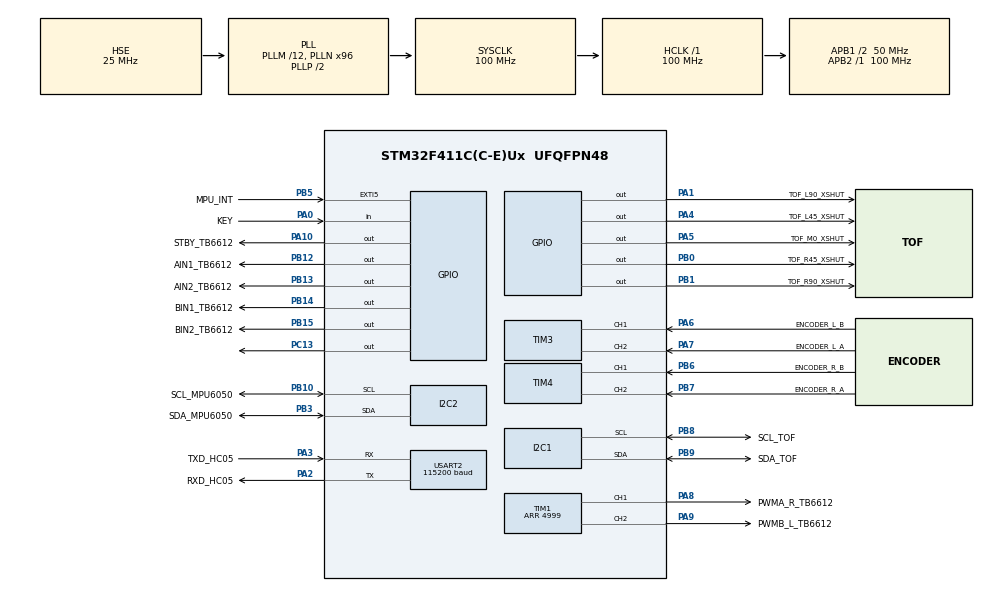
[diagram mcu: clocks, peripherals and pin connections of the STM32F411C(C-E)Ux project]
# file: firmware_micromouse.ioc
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Dma.Request0=USART2_RX
Dma.Request1=USART2_TX
Dma.USART2_RX.0.Direction=DMA_PERIPH_TO_MEMORY
Dma.USART2_RX.0.FIFOMode=DMA_FIFOMODE_DISABLE
Dma.USART2_RX.0.Instance=DMA1_Stream5
Dma.USART2_RX.0.MemDataAlignment=DMA_MDATAALIGN_BYTE
Dma.USART2_RX.0.MemInc=DMA_MINC_ENABLE
Dma.USART2_RX.0.Mode=DMA_CIRCULAR
Dma.USART2_RX.0.PeriphDataAlignment=DMA_PDATAALIGN_BYTE
Dma.USART2_RX.0.PeriphInc=DMA_PINC_DISABLE
Dma.USART2_RX.0.Priority=DMA_PRIORITY_LOW
Dma.USART2_TX.1.Direction=DMA_MEMORY_TO_PERIPH
Dma.USART2_TX.1.FIFOMode=DMA_FIFOMODE_DISABLE
Dma.USART2_TX.1.Instance=DMA1_Stream6
Dma.USART2_TX.1.MemDataAlignment=DMA_MDATAALIGN_BYTE
Dma.USART2_TX.1.MemInc=DMA_MINC_ENABLE
Dma.USART2_TX.1.Mode=DMA_NORMAL
Dma.USART2_TX.1.PeriphDataAlignment=DMA_PDATAALIGN_BYTE
Dma.USART2_TX.1.PeriphInc=DMA_PINC_DISABLE
Dma.USART2_TX.1.Priority=DMA_PRIORITY_LOW
I2C1.I2C_Mode=I2C_Fast
I2C2.I2C_Mode=I2C_Fast
Mcu.Family=STM32F4
Mcu.Name=STM32F411C(C-E)Ux
Mcu.Package=UFQFPN48
NVIC.DMA1_Stream5_IRQn=true\:3\:0\:false\:false\:true\:false\:true\:true
NVIC.DMA1_Stream6_IRQn=true\:3\:0\:false\:false\:true\:false\:true\:true
NVIC.EXTI9_5_IRQn=true\:2\:0\:false\:false\:true\:true\:true\:true
NVIC.PriorityGroup=NVIC_PRIORITYGROUP_4
NVIC.TIM2_IRQn=true\:1\:0\:false\:false\:true\:true\:true\:true
NVIC.USART2_IRQn=true\:3\:0\:false\:false\:true\:true\:true\:true
PA0-WKUP.GPIO_Label=KEY
PA0-WKUP.GPIO_PuPd=GPIO_PULLUP
PA0-WKUP.Signal=GPIO_Input
PA1.GPIO_Label=TOF_L90_XSHUT
PA1.Signal=GPIO_Output
PA10.GPIO_Label=STBY_TB6612
PA10.Signal=GPIO_Output
PA13.Mode=Serial_Wire
PA13.Signal=SYS_JTMS-SWDIO
PA14.Mode=Serial_Wire
PA14.Signal=SYS_JTCK-SWCLK
PA2.GPIO_Label=RXD_HC05
PA2.Mode=Asynchronous
PA2.Signal=USART2_TX
PA3.GPIO_Label=TXD_HC05
PA3.Mode=Asynchronous
PA3.Signal=USART2_RX
PA4.GPIO_Label=TOF_L45_XSHUT
PA4.Signal=GPIO_Output
PA5.GPIO_Label=TOF_M0_XSHUT
PA5.Signal=GPIO_Output
PA6.GPIO_Label=ENCODER_L_B
PA6.Signal=S_TIM3_CH1
PA7.GPIO_Label=ENCODER_L_A
PA7.Signal=S_TIM3_CH2
PA8.GPIO_Label=PWMA_R_TB6612
PA8.Signal=S_TIM1_CH1
PA9.GPIO_Label=PWMB_L_TB6612
PA9.Signal=S_TIM1_CH2
PB0.GPIO_Label=TOF_R45_XSHUT
PB0.Signal=GPIO_Output
PB1.GPIO_Label=TOF_R90_XSHUT
PB1.Signal=GPIO_Output
PB10.GPIO_Label=SCL_MPU6050
PB10.Mode=I2C
PB10.Signal=I2C2_SCL
PB12.GPIO_Label=AIN1_TB6612
PB12.Signal=GPIO_Output
PB13.GPIO_Label=AIN2_TB6612
PB13.Signal=GPIO_Output
PB14.GPIO_Label=BIN1_TB6612
PB14.Signal=GPIO_Output
PB15.GPIO_Label=BIN2_TB6612
PB15.Signal=GPIO_Output
PB3.GPIO_Label=SDA_MPU6050
PB3.Mode=I2C
PB3.Signal=I2C2_SDA
PB5.GPIO_Label=MPU_INT
PB5.Signal=GPXTI5
PB6.GPIO_Label=ENCODER_R_B
PB6.Signal=S_TIM4_CH1
PB7.GPIO_Label=ENCODER_R_A
PB7.Signal=S_TIM4_CH2
PB8.GPIO_Label=SCL_TOF
PB8.Mode=I2C
PB8.Signal=I2C1_SCL
PB9.GPIO_Label=SDA_TOF
PB9.Mode=I2C
PB9.Signal=I2C1_SDA
PC13-ANTI_TAMP.Signal=GPIO_Output
PH0\ -\ OSC_IN.Mode=HSE-External-Oscillator
PH0\ -\ OSC_IN.Signal=RCC_OSC_IN
PH1\ -\ OSC_OUT.Mode=HSE-External-Oscillator
PH1\ -\ OSC_OUT.Signal=RCC_OSC_OUT
ProjectManager.HeapSize=0x200
ProjectManager.StackSize=0x400
ProjectManager.TargetToolchain=CMake
RCC.48MHZClocksFreq_Value=50000000
RCC.AHBFreq_Value=100000000
RCC.APB1CLKDivider=RCC_HCLK_DIV2
RCC.APB1Freq_Value=50000000
RCC.APB1TimFreq_Value=100000000
RCC.APB2Freq_Value=100000000
RCC.APB2TimFreq_Value=100000000
RCC.CortexFreq_Value=100000000
RCC.HCLKFreq_Value=100000000
RCC.HSE_VALUE=25000000
RCC.HSI_VALUE=16000000
RCC.LSE_VALUE=32768
RCC.PLLM=12
RCC.PLLN=96
RCC.PLLSourceVirtual=RCC_PLLSOURCE_HSE
RCC.SYSCLKFreq_VALUE=100000000
RCC.SYSCLKSource=RCC_SYSCLKSOURCE_PLLCLK
RCC.VCOOutputFreq_Value=200000000
SH.S_TIM1_CH1.0=TIM1_CH1,PWM Generation1 CH1
SH.S_TIM1_CH2.0=TIM1_CH2,PWM Generation2 CH2
SH.S_TIM3_CH1.0=TIM3_CH1,Encoder_Interface
SH.S_TIM3_CH2.0=TIM3_CH2,Encoder_Interface
SH.S_TIM4_CH1.0=TIM4_CH1,Encoder_Interface
SH.S_TIM4_CH2.0=TIM4_CH2,Encoder_Interface
TIM1.Channel-PWM\ Generation1\ CH1=TIM_CHANNEL_1
TIM1.Channel-PWM\ Generation2\ CH2=TIM_CHANNEL_2
TIM1.Period=4999
TIM2.Period=999
TIM2.Prescaler=99
TIM3.EncoderMode=TIM_ENCODERMODE_TI12
TIM3.IC1Filter=6
TIM3.IC2Filter=6
TIM4.EncoderMode=TIM_ENCODERMODE_TI12
TIM4.IC1Filter=6
TIM4.IC2Filter=6
USART2.BaudRate=115200
USART2.VirtualMode=VM_ASYNC
VP_TIM2_VS_ClockSourceINT.Mode=Internal
board=custom

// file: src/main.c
/* USER CODE BEGIN Header */
/**
  ******************************************************************************
  * @file           : main.c
  * @brief          : Main program body
  ******************************************************************************
  * @attention
  *
  * Copyright (c) 2026 STMicroelectronics.
  * All rights reserved.
  *
  * This software is licensed under terms that can be found in the LICENSE file
  * in the root directory of this software component.
  * If no LICENSE file comes with this software, it is provided AS-IS.
  *
  ******************************************************************************
  */
/* USER CODE END Header */
#include "main.h"

/* USER CODE BEGIN Includes */
#ifdef HW_TEST
#include "hwtest/hwtest.h" /* firmware test phần cứng (env hwtest) */
#endif

/* USER CODE END Includes */

I2C_HandleTypeDef hi2c1;
I2C_HandleTypeDef hi2c2;

TIM_HandleTypeDef htim1;
TIM_HandleTypeDef htim2;
TIM_HandleTypeDef htim3;
TIM_HandleTypeDef htim4;

UART_HandleTypeDef huart2;
DMA_HandleTypeDef hdma_usart2_rx;
DMA_HandleTypeDef hdma_usart2_tx;

void SystemClock_Config(void);
static void MX_GPIO_Init(void);
static void MX_DMA_Init(void);
static void MX_I2C1_Init(void);
static void MX_I2C2_Init(void);
static void MX_TIM1_Init(void);
static void MX_TIM3_Init(void);
static void MX_TIM4_Init(void);
static void MX_USART2_UART_Init(void);
static void MX_TIM2_Init(void);

int main(void)
{

  /* MCU Configuration--------------------------------------------------------*/

  /* Reset of all peripherals, Initializes the Flash interface and the Systick. */
  HAL_Init();

  /* Configure the system clock */
  SystemClock_Config();

  /* Initialize all configured peripherals */
  MX_GPIO_Init();
  MX_DMA_Init();
  MX_I2C1_Init();
  MX_I2C2_Init();
  MX_TIM1_Init();
  MX_TIM3_Init();
  MX_TIM4_Init();
  MX_USART2_UART_Init();
  MX_TIM2_Init();
  /* USER CODE BEGIN 2 */
#ifdef HW_TEST
  hwtest_run();
#endif

  /* USER CODE END 2 */

  /* Infinite loop */
  while (1)
  {

  }
}

void SystemClock_Config(void)
{
  RCC_OscInitTypeDef RCC_OscInitStruct = {0};
  RCC_ClkInitTypeDef RCC_ClkInitStruct = {0};

  /** Configure the main internal regulator output voltage
  */
  __HAL_RCC_PWR_CLK_ENABLE();
  __HAL_PWR_VOLTAGESCALING_CONFIG(PWR_REGULATOR_VOLTAGE_SCALE1);

  /** Initializes the RCC Oscillators according to the specified parameters
  * in the RCC_OscInitTypeDef structure.
  */
  RCC_OscInitStruct.OscillatorType = RCC_OSCILLATORTYPE_HSE;
  RCC_OscInitStruct.HSEState = RCC_HSE_ON;
  RCC_OscInitStruct.PLL.PLLState = RCC_PLL_ON;
  RCC_OscInitStruct.PLL.PLLSource = RCC_PLLSOURCE_HSE;
  RCC_OscInitStruct.PLL.PLLM = 12;
  RCC_OscInitStruct.PLL.PLLN = 96;
  RCC_OscInitStruct.PLL.PLLP = RCC_PLLP_DIV2;
  RCC_OscInitStruct.PLL.PLLQ = 4;
  if (HAL_RCC_OscConfig(&RCC_OscInitStruct) != HAL_OK)
  {
    Error_Handler();
  }

  /** Initializes the CPU, AHB and APB buses clocks
  */
  RCC_ClkInitStruct.ClockType = RCC_CLOCKTYPE_HCLK|RCC_CLOCKTYPE_SYSCLK
                              |RCC_CLOCKTYPE_PCLK1|RCC_CLOCKTYPE_PCLK2;
  RCC_ClkInitStruct.SYSCLKSource = RCC_SYSCLKSOURCE_PLLCLK;
  RCC_ClkInitStruct.AHBCLKDivider = RCC_SYSCLK_DIV1;
  RCC_ClkInitStruct.APB1CLKDivider = RCC_HCLK_DIV2;
  RCC_ClkInitStruct.APB2CLKDivider = RCC_HCLK_DIV1;

  if (HAL_RCC_ClockConfig(&RCC_ClkInitStruct, FLASH_LATENCY_3) != HAL_OK)
  {
    Error_Handler();
  }
}

static void MX_I2C1_Init(void)
{

  hi2c1.Instance = I2C1;
  hi2c1.Init.ClockSpeed = 400000;
  hi2c1.Init.DutyCycle = I2C_DUTYCYCLE_2;
  hi2c1.Init.OwnAddress1 = 0;
  hi2c1.Init.AddressingMode = I2C_ADDRESSINGMODE_7BIT;
  hi2c1.Init.DualAddressMode = I2C_DUALADDRESS_DISABLE;
  hi2c1.Init.OwnAddress2 = 0;
  hi2c1.Init.GeneralCallMode = I2C_GENERALCALL_DISABLE;
  hi2c1.Init.NoStretchMode = I2C_NOSTRETCH_DISABLE;
  if (HAL_I2C_Init(&hi2c1) != HAL_OK)
  {
    Error_Handler();
  }

}

static void MX_I2C2_Init(void)
{

  hi2c2.Instance = I2C2;
  hi2c2.Init.ClockSpeed = 400000;
  hi2c2.Init.DutyCycle = I2C_DUTYCYCLE_2;
  hi2c2.Init.OwnAddress1 = 0;
  hi2c2.Init.AddressingMode = I2C_ADDRESSINGMODE_7BIT;
  hi2c2.Init.DualAddressMode = I2C_DUALADDRESS_DISABLE;
  hi2c2.Init.OwnAddress2 = 0;
  hi2c2.Init.GeneralCallMode = I2C_GENERALCALL_DISABLE;
  hi2c2.Init.NoStretchMode = I2C_NOSTRETCH_DISABLE;
  if (HAL_I2C_Init(&hi2c2) != HAL_OK)
  {
    Error_Handler();
  }

}

static void MX_TIM1_Init(void)
{

  TIM_MasterConfigTypeDef sMasterConfig = {0};
  TIM_OC_InitTypeDef sConfigOC = {0};
  TIM_BreakDeadTimeConfigTypeDef sBreakDeadTimeConfig = {0};

  htim1.Instance = TIM1;
  htim1.Init.Prescaler = 0;
  htim1.Init.CounterMode = TIM_COUNTERMODE_UP;
  htim1.Init.Period = 4999;
  htim1.Init.ClockDivision = TIM_CLOCKDIVISION_DIV1;
  htim1.Init.RepetitionCounter = 0;
  htim1.Init.AutoReloadPreload = TIM_AUTORELOAD_PRELOAD_DISABLE;
  if (HAL_TIM_PWM_Init(&htim1) != HAL_OK)
  {
    Error_Handler();
  }
  sMasterConfig.MasterOutputTrigger = TIM_TRGO_RESET;
  sMasterConfig.MasterSlaveMode = TIM_MASTERSLAVEMODE_DISABLE;
  if (HAL_TIMEx_MasterConfigSynchronization(&htim1, &sMasterConfig) != HAL_OK)
  {
    Error_Handler();
  }
  sConfigOC.OCMode = TIM_OCMODE_PWM1;
  sConfigOC.Pulse = 0;
  sConfigOC.OCPolarity = TIM_OCPOLARITY_HIGH;
  sConfigOC.OCNPolarity = TIM_OCNPOLARITY_HIGH;
  sConfigOC.OCFastMode = TIM_OCFAST_DISABLE;
  sConfigOC.OCIdleState = TIM_OCIDLESTATE_RESET;
  sConfigOC.OCNIdleState = TIM_OCNIDLESTATE_RESET;
  if (HAL_TIM_PWM_ConfigChannel(&htim1, &sConfigOC, TIM_CHANNEL_1) != HAL_OK)
  {
    Error_Handler();
  }
  if (HAL_TIM_PWM_ConfigChannel(&htim1, &sConfigOC, TIM_CHANNEL_2) != HAL_OK)
  {
    Error_Handler();
  }
  sBreakDeadTimeConfig.OffStateRunMode = TIM_OSSR_DISABLE;
  sBreakDeadTimeConfig.OffStateIDLEMode = TIM_OSSI_DISABLE;
  sBreakDeadTimeConfig.LockLevel = TIM_LOCKLEVEL_OFF;
  sBreakDeadTimeConfig.DeadTime = 0;
  sBreakDeadTimeConfig.BreakState = TIM_BREAK_DISABLE;
  sBreakDeadTimeConfig.BreakPolarity = TIM_BREAKPOLARITY_HIGH;
  sBreakDeadTimeConfig.AutomaticOutput = TIM_AUTOMATICOUTPUT_DISABLE;
  if (HAL_TIMEx_ConfigBreakDeadTime(&htim1, &sBreakDeadTimeConfig) != HAL_OK)
  {
    Error_Handler();
  }
  HAL_TIM_MspPostInit(&htim1);

}

static void MX_TIM2_Init(void)
{

  TIM_ClockConfigTypeDef sClockSourceConfig = {0};
  TIM_MasterConfigTypeDef sMasterConfig = {0};

  htim2.Instance = TIM2;
  htim2.Init.Prescaler = 99;
  htim2.Init.CounterMode = TIM_COUNTERMODE_UP;
  htim2.Init.Period = 999;
  htim2.Init.ClockDivision = TIM_CLOCKDIVISION_DIV1;
  htim2.Init.AutoReloadPreload = TIM_AUTORELOAD_PRELOAD_DISABLE;
  if (HAL_TIM_Base_Init(&htim2) != HAL_OK)
  {
    Error_Handler();
  }
  sClockSourceConfig.ClockSource = TIM_CLOCKSOURCE_INTERNAL;
  if (HAL_TIM_ConfigClockSource(&htim2, &sClockSourceConfig) != HAL_OK)
  {
    Error_Handler();
  }
  sMasterConfig.MasterOutputTrigger = TIM_TRGO_RESET;
  sMasterConfig.MasterSlaveMode = TIM_MASTERSLAVEMODE_DISABLE;
  if (HAL_TIMEx_MasterConfigSynchronization(&htim2, &sMasterConfig) != HAL_OK)
  {
    Error_Handler();
  }

}

static void MX_TIM3_Init(void)
{

  TIM_Encoder_InitTypeDef sConfig = {0};
  TIM_MasterConfigTypeDef sMasterConfig = {0};

  htim3.Instance = TIM3;
  htim3.Init.Prescaler = 0;
  htim3.Init.CounterMode = TIM_COUNTERMODE_UP;
  htim3.Init.Period = 65535;
  htim3.Init.ClockDivision = TIM_CLOCKDIVISION_DIV1;
  htim3.Init.AutoReloadPreload = TIM_AUTORELOAD_PRELOAD_DISABLE;
  sConfig.EncoderMode = TIM_ENCODERMODE_TI12;
  sConfig.IC1Polarity = TIM_ICPOLARITY_RISING;
  sConfig.IC1Selection = TIM_ICSELECTION_DIRECTTI;
  sConfig.IC1Prescaler = TIM_ICPSC_DIV1;
  sConfig.IC1Filter = 6;
  sConfig.IC2Polarity = TIM_ICPOLARITY_RISING;
  sConfig.IC2Selection = TIM_ICSELECTION_DIRECTTI;
  sConfig.IC2Prescaler = TIM_ICPSC_DIV1;
  sConfig.IC2Filter = 6;
  if (HAL_TIM_Encoder_Init(&htim3, &sConfig) != HAL_OK)
  {
    Error_Handler();
  }
  sMasterConfig.MasterOutputTrigger = TIM_TRGO_RESET;
  sMasterConfig.MasterSlaveMode = TIM_MASTERSLAVEMODE_DISABLE;
  if (HAL_TIMEx_MasterConfigSynchronization(&htim3, &sMasterConfig) != HAL_OK)
  {
    Error_Handler();
  }

}

static void MX_TIM4_Init(void)
{

  TIM_Encoder_InitTypeDef sConfig = {0};
  TIM_MasterConfigTypeDef sMasterConfig = {0};

  htim4.Instance = TIM4;
  htim4.Init.Prescaler = 0;
  htim4.Init.CounterMode = TIM_COUNTERMODE_UP;
  htim4.Init.Period = 65535;
  htim4.Init.ClockDivision = TIM_CLOCKDIVISION_DIV1;
  htim4.Init.AutoReloadPreload = TIM_AUTORELOAD_PRELOAD_DISABLE;
  sConfig.EncoderMode = TIM_ENCODERMODE_TI12;
  sConfig.IC1Polarity = TIM_ICPOLARITY_RISING;
  sConfig.IC1Selection = TIM_ICSELECTION_DIRECTTI;
  sConfig.IC1Prescaler = TIM_ICPSC_DIV1;
  sConfig.IC1Filter = 6;
  sConfig.IC2Polarity = TIM_ICPOLARITY_RISING;
  sConfig.IC2Selection = TIM_ICSELECTION_DIRECTTI;
  sConfig.IC2Prescaler = TIM_ICPSC_DIV1;
  sConfig.IC2Filter = 6;
  if (HAL_TIM_Encoder_Init(&htim4, &sConfig) != HAL_OK)
  {
    Error_Handler();
  }
  sMasterConfig.MasterOutputTrigger = TIM_TRGO_RESET;
  sMasterConfig.MasterSlaveMode = TIM_MASTERSLAVEMODE_DISABLE;
  if (HAL_TIMEx_MasterConfigSynchronization(&htim4, &sMasterConfig) != HAL_OK)
  {
    Error_Handler();
  }

}

static void MX_USART2_UART_Init(void)
{

  huart2.Instance = USART2;
  huart2.Init.BaudRate = 115200;
  huart2.Init.WordLength = UART_WORDLENGTH_8B;
  huart2.Init.StopBits = UART_STOPBITS_1;
  huart2.Init.Parity = UART_PARITY_NONE;
  huart2.Init.Mode = UART_MODE_TX_RX;
  huart2.Init.HwFlowCtl = UART_HWCONTROL_NONE;
  huart2.Init.OverSampling = UART_OVERSAMPLING_16;
  if (HAL_UART_Init(&huart2) != HAL_OK)
  {
    Error_Handler();
  }

}

static void MX_DMA_Init(void)
{

  /* DMA controller clock enable */
  __HAL_RCC_DMA1_CLK_ENABLE();

  /* DMA interrupt init */
  /* DMA1_Stream5_IRQn interrupt configuration */
  HAL_NVIC_SetPriority(DMA1_Stream5_IRQn, 3, 0);
  HAL_NVIC_EnableIRQ(DMA1_Stream5_IRQn);
  /* DMA1_Stream6_IRQn interrupt configuration */
  HAL_NVIC_SetPriority(DMA1_Stream6_IRQn, 3, 0);
  HAL_NVIC_EnableIRQ(DMA1_Stream6_IRQn);

}

static void MX_GPIO_Init(void)
{
  GPIO_InitTypeDef GPIO_InitStruct = {0};

  /* GPIO Ports Clock Enable */
  __HAL_RCC_GPIOC_CLK_ENABLE();
  __HAL_RCC_GPIOH_CLK_ENABLE();
  __HAL_RCC_GPIOA_CLK_ENABLE();
  __HAL_RCC_GPIOB_CLK_ENABLE();

  /*Configure GPIO pin Output Level */
  HAL_GPIO_WritePin(GPIOC, GPIO_PIN_13, GPIO_PIN_RESET);

  /*Configure GPIO pin Output Level */
  HAL_GPIO_WritePin(GPIOA, TOF_L90_XSHUT_Pin|TOF_L45_XSHUT_Pin|TOF_M0_XSHUT_Pin|STBY_TB6612_Pin, GPIO_PIN_RESET);

  /*Configure GPIO pin Output Level */
  HAL_GPIO_WritePin(GPIOB, TOF_R45_XSHUT_Pin|TOF_R90_XSHUT_Pin|AIN1_TB6612_Pin|AIN2_TB6612_Pin
                          |BIN1_TB6612_Pin|BIN2_TB6612_Pin, GPIO_PIN_RESET);

  /*Configure GPIO pin : PC13 */
  GPIO_InitStruct.Pin = GPIO_PIN_13;
  GPIO_InitStruct.Mode = GPIO_MODE_OUTPUT_PP;
  GPIO_InitStruct.Pull = GPIO_NOPULL;
  GPIO_InitStruct.Speed = GPIO_SPEED_FREQ_LOW;
  HAL_GPIO_Init(GPIOC, &GPIO_InitStruct);

  /*Configure GPIO pin : KEY_Pin */
  GPIO_InitStruct.Pin = KEY_Pin;
  GPIO_InitStruct.Mode = GPIO_MODE_INPUT;
  GPIO_InitStruct.Pull = GPIO_PULLUP;
  HAL_GPIO_Init(KEY_GPIO_Port, &GPIO_InitStruct);

  /*Configure GPIO pins : TOF_L90_XSHUT_Pin TOF_L45_XSHUT_Pin TOF_M0_XSHUT_Pin STBY_TB6612_Pin */
  GPIO_InitStruct.Pin = TOF_L90_XSHUT_Pin|TOF_L45_XSHUT_Pin|TOF_M0_XSHUT_Pin|STBY_TB6612_Pin;
  GPIO_InitStruct.Mode = GPIO_MODE_OUTPUT_PP;
  GPIO_InitStruct.Pull = GPIO_NOPULL;
  GPIO_InitStruct.Speed = GPIO_SPEED_FREQ_LOW;
  HAL_GPIO_Init(GPIOA, &GPIO_InitStruct);

  /*Configure GPIO pins : TOF_R45_XSHUT_Pin TOF_R90_XSHUT_Pin AIN1_TB6612_Pin AIN2_TB6612_Pin
                           BIN1_TB6612_Pin BIN2_TB6612_Pin */
  GPIO_InitStruct.Pin = TOF_R45_XSHUT_Pin|TOF_R90_XSHUT_Pin|AIN1_TB6612_Pin|AIN2_TB6612_Pin
                          |BIN1_TB6612_Pin|BIN2_TB6612_Pin;
  GPIO_InitStruct.Mode = GPIO_MODE_OUTPUT_PP;
  GPIO_InitStruct.Pull = GPIO_NOPULL;
  GPIO_InitStruct.Speed = GPIO_SPEED_FREQ_LOW;
  HAL_GPIO_Init(GPIOB, &GPIO_InitStruct);

  /*Configure GPIO pin : MPU_INT_Pin */
  GPIO_InitStruct.Pin = MPU_INT_Pin;
  GPIO_InitStruct.Mode = GPIO_MODE_IT_RISING;
  GPIO_InitStruct.Pull = GPIO_NOPULL;
  HAL_GPIO_Init(MPU_INT_GPIO_Port, &GPIO_InitStruct);

  /* EXTI interrupt init*/
  HAL_NVIC_SetPriority(EXTI9_5_IRQn, 2, 0);
  HAL_NVIC_EnableIRQ(EXTI9_5_IRQn);

}

void Error_Handler(void)
{
  __disable_irq();
  while (1)
  {
  }
}
